# M36B register map
File version: 0.1
CPU: 
Registers are 32-bit, read-write, reset 0x0 unless marked. A register's access mark holds for its fields unless they carry their own. Offsets are from the block's base; [hi:lo] are bit positions; {n}, {i} and the like mark numbered series.

## DMAA — DMA Controller
Base 0x4004C000
Same registers: DMAB 0x4004D000
0x00 STATUS ro reset 0x101F0000 — DMA Status Register
  [0] MASTER_ENABLE
0x04 CFG wo reset not defined — DMA Configuration Register
  [0] MASTER_ENABLE
0x08 CTRLBASEPTR — DMA Control Data Base Pointer Register
  [31:10] CTRL_BASE_PTR
0x0C ALTCTRLBASEPTR ro — DMA Channel Alternate Control Data Base Pointer Register
  [31:0] ALT_CTRL_BASE_PTR
0x14 CHNLSWREQUEST wo reset not defined — DMA Channel Software Request Register
  [31:0] CHNL_SW_REQUEST
0x18 CHNLUSEBURSTSET — DMA Channel Useburst Set Register
  [31:0] CHNL_USEBURST_SET
0x1C CHNLUSEBURSTCLR wo reset not defined — DMA Channel Useburst Clear Register
  [31:0] CHNL_USEBURST_CLR
0x20 CHNLREQMASKSET — DMA Channel Request Mask Set Register
  [31:0] CHNL_REQ_MASK_SET
0x24 CHNLREQMASKCLR wo reset not defined — DMA Channel Request Mask Clear Register
  [31:0] CHNL_REQ_MASK_CLR
0x28 CHNLENABLESET — DMA Channel Enable Set Register
  [31:0] CHNL_ENABLE_SET
0x2C CHNLENABLECLR wo reset not defined — DMA Channel Enable Clear Register
  [31:0] CHNL_ENABLE_CLR
0x30 CHNLPRIALTSET — DMA Channel Primary-Alternate Set Register
  [31:0] CHNL_PRI_ALT_SET
0x34 CHNLPRIALTCLR wo reset not defined — DMA Channel Primary-Alternate Clear Register
  [31:0] CHNL_PRI_ALT_CLR
0x38 CHNLPRIORITYSET — DMA Channel Priority Set Register
  [31:0] CHNL_PRIORITY_SET
0x3C CHNLPRIORITYCLR wo reset not defined — DMA Channel Priority Clear Register
  [31:0] CHNL_PRIORITY_CLR
0x4C ERRCLR — DMA Bus Error Clear Register
  [0] ERR_CLR

## AD — Analog-to-Digital Converter (AD)
Base 0x40050000
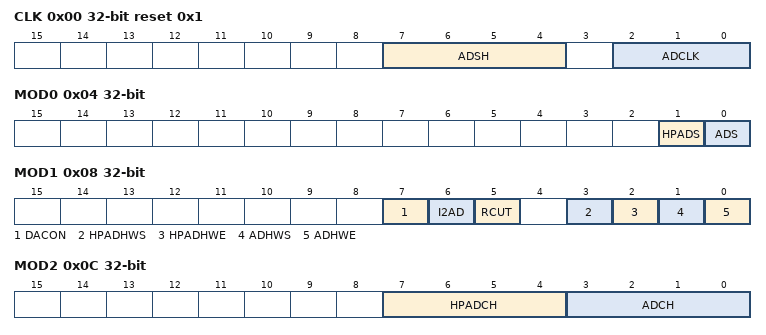
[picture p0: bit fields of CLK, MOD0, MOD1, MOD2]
0x00 CLK reset 0x1 — AD Conversion Clock Setting Register
  [7:4] ADSH, [2:0] ADCLK
0x04 MOD0 wo — AD Mode Control Register 0
  [1] HPADS, [0] ADS
0x08 MOD1 — AD Mode Control Register 1
  [7] DACON, [6] I2AD, [5] RCUT, [3] HPADHWS, [2] HPADHWE, [1] ADHWS, [0] ADHWE
0x0C MOD2 — AD Mode Control Register 2
  [7:4] HPADCH, [3:0] ADCH
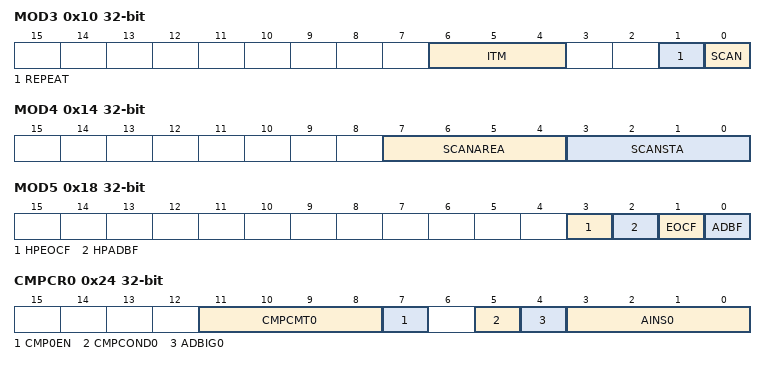
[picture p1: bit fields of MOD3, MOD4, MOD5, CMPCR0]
0x10 MOD3 — AD Mode Control Register 3
  [6:4] ITM, [1] REPEAT, [0] SCAN
0x14 MOD4 — AD Mode Control Register 4
  [7:4] SCANAREA, [3:0] SCANSTA
0x18 MOD5 ro — AD Mode Control Register 5
  [3] HPEOCF, [2] HPADBF, [1] EOCF, [0] ADBF
0x1C MOD6 wo — AD Mode Control Register 6
  [1:0] ADRST
0x24 CMPCR0 — AD Monitoring Setting Register 0
  [11:8] CMPCMT0, [7] CMP0EN, [5] CMPCOND0, [4] ADBIG0, [3:0] AINS0
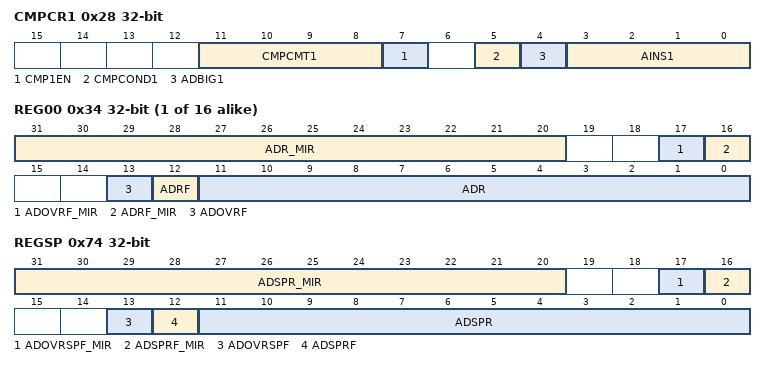
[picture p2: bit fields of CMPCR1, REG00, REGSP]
0x28 CMPCR1 — AD Monitoring Setting Register 1
  [11:8] CMPCMT1, [7] CMP1EN, [5] CMPCOND1, [4] ADBIG1, [3:0] AINS1
0x2C CMP0 — AD Conversion Result Comparison Register 0
  [11:0] AD0CMP
0x30 CMP1 — AD Conversion Result Comparison Register 1
  [11:0] AD1CMP
{0x34+4i} REG{i:02} ro (i=0..15) — AD Conversion Result Register {i:02}
  [31:20] ADR_MIR, [17] ADOVRF_MIR, [16] ADRF_MIR, [13] ADOVRF, [12] ADRF, [11:0] ADR
0x74 REGSP ro — AD Conversion Result Register SP
  [31:20] ADSPR_MIR, [17] ADOVRSPF_MIR, [16] ADSPRF_MIR, [13] ADOVRSPF, [12] ADSPRF, [11:0] ADSPR

## EXB — External Bus Interface(EXB)
Base 0x4005C000
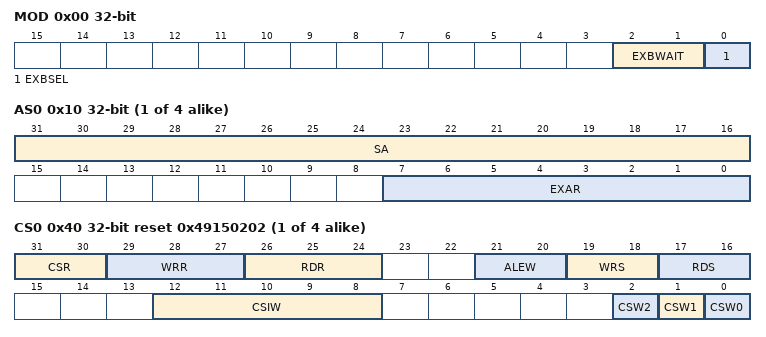
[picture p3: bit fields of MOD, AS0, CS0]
0x00 MOD — External Bus Mode Register
  [2:1] EXBWAIT, [0] EXBSEL
{0x10+4i} AS{i} (i=0..3) — External Bus Base Address and CS Space setting Register {i}
  [31:16] SA, [7:0] EXAR
{0x40+4i} CS{i} reset 0x49150202 (i=0..3) — Chip Select and Wait Controller Register {i}
  [31:30] CSR, [29:27] WRR, [26:24] RDR, [21:20] ALEW, [19:18] WRS, [17:16] RDS, [12:8] CSIW, [2] CSW2, [1] CSW1, [0] CSW0

## ADILV — ADC
Base 0x40066000
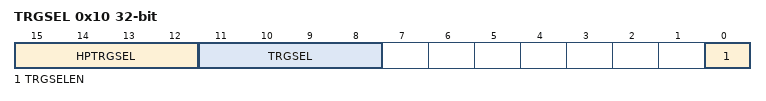
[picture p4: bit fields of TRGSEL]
0x10 TRGSEL — Trigger Select Register
  [15:12] HPTRGSEL, [11:8] TRGSEL, [0] TRGSELEN

## PA — General Purpose Input_Output Port (PA)
Base 0x400C0000
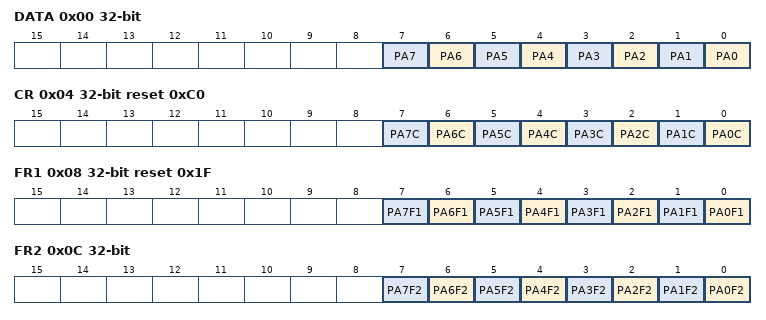
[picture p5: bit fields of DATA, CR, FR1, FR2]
0x00 DATA — PA Data Register
  [n] PA{n} (n=0..7)
0x04 CR reset 0xC0 — PA Control Register
  [n] PA{n}C (n=0..7)
0x08 FR1 reset 0x1F — PA Function Register 1
  [n] PA{n}F1 (n=0..7)
0x0C FR2 — PA Function Register 2
  [n] PA{n}F2 (n=0..7)
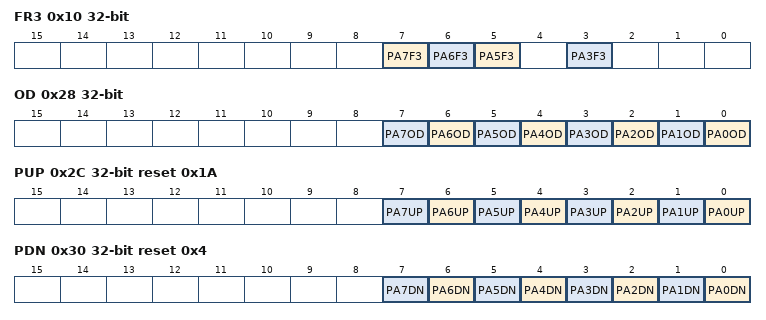
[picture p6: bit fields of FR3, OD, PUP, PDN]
0x10 FR3 — PA Function Register 3
  [7] PA7F3, [6] PA6F3, [5] PA5F3, [3] PA3F3
0x14 FR4 — PA Function Register 4
  [7] PA7F4
0x18 FR5 — PA Function Register 5
  [7] PA7F5
0x28 OD — PA Open Drain Control Register
  [n] PA{n}OD (n=0..7)
0x2C PUP reset 0x1A — PA Pull-Up Control Register
  [n] PA{n}UP (n=0..7)
0x30 PDN reset 0x4 — PA Pull-Down Control Register
  [n] PA{n}DN (n=0..7)
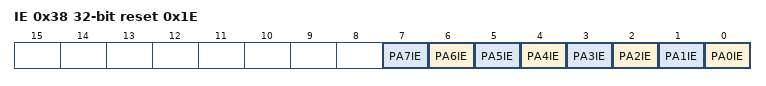
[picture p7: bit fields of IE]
0x38 IE reset 0x1E — PA Input Enable Control Register
  [n] PA{n}IE (n=0..7)
